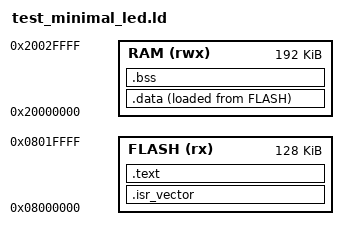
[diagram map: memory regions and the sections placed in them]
/**
 * 链接脚本 - STM32F427 最小测试
 */

MEMORY
{
    FLASH (rx) : ORIGIN = 0x08000000, LENGTH = 128K
    RAM (rwx)  : ORIGIN = 0x20000000, LENGTH = 192K
}

_estack = ORIGIN(RAM) + LENGTH(RAM);  /* 栈顶 */

SECTIONS
{
    .isr_vector :
    {
        KEEP(*(.isr_vector))
    } > FLASH

    .text :
    {
        *(.text*)
        *(.rodata*)
    } > FLASH

    .data :
    {
        *(.data*)
    } > RAM AT > FLASH

    .bss :
    {
        *(.bss*)
        *(COMMON)
    } > RAM
}
